# GPMC register map
Vendor: Texas Instruments
Peripheral module from a debugger description file (folder am335x).
Registers are 32-bit, access per field, no defined reset value unless marked. A register's access mark holds for its fields unless they carry their own. Offsets are as the file gives them; lines under a group give offsets from that group; [hi:lo] are bit positions; {n}, {i} and the like mark numbered series; 'fields as' and 'values as' point back to an identical list; <NAME> marks a mode.

## GPMC
0x00 GPMC_REVISION ro — The GPMC_REVISION register contains the IP revision code.
  [7:0] REV — IP revision. Major revision is [7:4]. Minor revision is [3:0]. Examples: 10h for revision 1.0, 21h for revision 2.1.
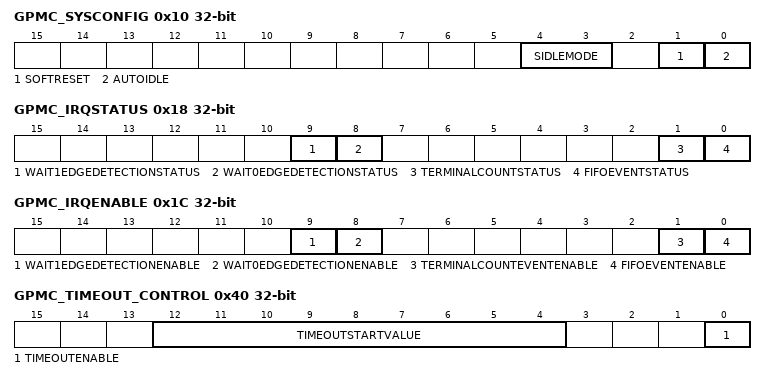
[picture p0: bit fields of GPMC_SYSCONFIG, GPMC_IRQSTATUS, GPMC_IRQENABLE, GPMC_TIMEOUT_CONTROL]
0x10 GPMC_SYSCONFIG — The GPMC_SYSCONFIG register controls the various parameters of the OCP interface.
  [4:3] SIDLEMODE rw — Idle mode
  [1] SOFTRESET rw — Software reset (Set 1 to this bit triggers a module reset. This bit is automatically reset by hardware. During reads, it always returns 0).
  [0] AUTOIDLE rw — Internal OCP clock gating strategy.
0x14 GPMC_SYSSTATUS ro — The GPMC_SYSSTATUS register provides status information about the module, excluding the interrupt status information.
  [0] RESETDONE — Internal reset monitoring
0x18 GPMC_IRQSTATUS — The GPMC_IRQSTATUS interrupt status register regroups all the status of the module internal events that can generate an interrupt.
  [9] WAIT1EDGEDETECTIONSTATUS rw — Status of the Wait1 Edge Detection interrupt
  [8] WAIT0EDGEDETECTIONSTATUS rw — Status of the Wait0 Edge Detection interrupt
  [1] TERMINALCOUNTSTATUS rw — Status of the TerminalCountEvent interrupt
  [0] FIFOEVENTSTATUS rw — Status of the FIFOEvent interrupt
0x1C GPMC_IRQENABLE — The GPMC_IRQENABLE interrupt enable register allows to mask/unmask the module internal sources of interrupt, on a event-by-event basis.
  [9] WAIT1EDGEDETECTIONENABLE rw — Enables the Wait1 Edge Detection interrupt
  [8] WAIT0EDGEDETECTIONENABLE rw — Enables the Wait0 Edge Detection interrupt
  [1] TERMINALCOUNTEVENTENABLE rw — Enables TerminalCountEvent interrupt issuing in pre-fetch or write posting mode
  [0] FIFOEVENTENABLE rw — Enables the FIFOEvent interrupt
0x40 GPMC_TIMEOUT_CONTROL — The GPMC_TIMEOUT_CONTROL register allows the user to set the start value of the timeout counter
  [12:4] TIMEOUTSTARTVALUE rw — Start value of the time-out counter (000 corresponds to 0 GPMC.FCLK cycle, 1h corresponds to 1 GPMC.FCLK cycle, and 1FFh corresponds to 511 GPMC.FCLK cycles)
  [0] TIMEOUTENABLE rw — Enable bit of the TimeOut feature
0x44 GPMC_ERR_ADDRESS — The GPMC_ERR_ADDRESS register stores the address of the illegal access when an error occurs.
  [30:0] ILLEGALADD rw — Address of illegal access: A30 (0 for memory region, 1 for GPMC register region) and A29 to A0 (1GByte maximum)
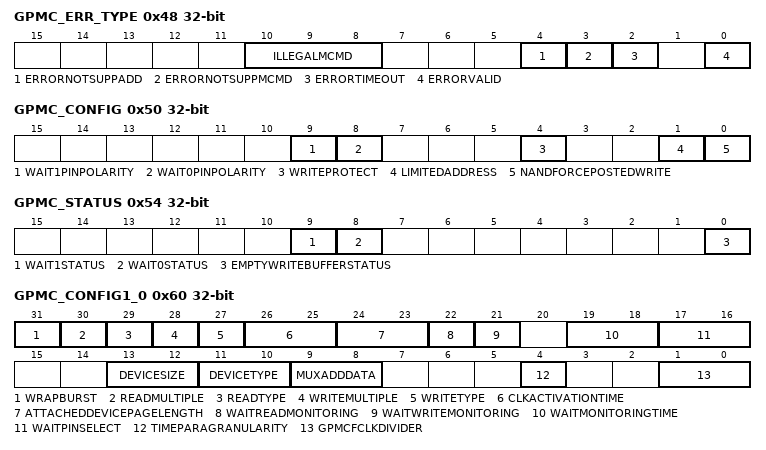
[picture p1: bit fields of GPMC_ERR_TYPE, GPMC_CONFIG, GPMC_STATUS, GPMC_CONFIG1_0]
0x48 GPMC_ERR_TYPE — The GPMC_ERR_TYPE register stores the type of error when an error occurs.
  [10:8] ILLEGALMCMD rw — System Command of the transaction that caused the error
  [4] ERRORNOTSUPPADD rw — Not supported Address error
  [3] ERRORNOTSUPPMCMD rw — Not supported Command error
  [2] ERRORTIMEOUT rw — Time-out error
  [0] ERRORVALID rw — Error validity status - Must be explicitly cleared with a write 1 transaction
0x50 GPMC_CONFIG — The configuration register allows global configuration of the GPMC.
  [9] WAIT1PINPOLARITY rw — Selects the polarity of input pin WAIT1.
  [8] WAIT0PINPOLARITY rw — Selects the polarity of input pin WAIT0.
  [4] WRITEPROTECT rw — Controls the WP output pin level.
  [1] LIMITEDADDRESS rw — Limited Address device support.
  [0] NANDFORCEPOSTEDWRITE rw
0x54 GPMC_STATUS — The status register provides global status bits of the GPMC.
  [9] WAIT1STATUS rw — Is a copy of input pin WAIT1. (Reset value is WAIT1 input pin sampled at IC reset)
  [8] WAIT0STATUS rw — Is a copy of input pin WAIT0. (Reset value is WAIT0 input pin sampled at IC reset)
  [0] EMPTYWRITEBUFFERSTATUS rw — Stores the empty status of the write buffer
0x60 GPMC_CONFIG1_0 — The configuration 1 register sets signal control parameters per chip select.
  [31] WRAPBURST rw — Enables the wrapping burst capability. Must be set if the attached device is configured in wrapping burst
  [30] READMULTIPLE rw — Selects the read single or multiple access
  [29] READTYPE rw — Selects the read mode operation
  [28] WRITEMULTIPLE rw — Selects the write single or multiple access
  [27] WRITETYPE rw — Selects the write mode operation
  [26:25] CLKACTIVATIONTIME rw — Output GPMC.CLK activation time
  [24:23] ATTACHEDDEVICEPAGELENGTH rw — Specifies the attached device page (burst) length (1 Word = Interface size)
  [22] WAITREADMONITORING rw — Selects the Wait monitoring configuration for Read accesses.
  [21] WAITWRITEMONITORING rw — Selects the Wait monitoring configuration for Write accesses
  [19:18] WAITMONITORINGTIME rw — Selects input pin Wait monitoring time
  [17:16] WAITPINSELECT rw — Selects the input WAIT pin for this chip select.
  [13:12] DEVICESIZE rw — Selects the device size attached (Reset value is SYSBOOT[8] input pin sampled at IC reset for CS[0] (active low) and 01 for CS[1] to CS[6] (active low)).
  [11:10] DEVICETYPE rw — Selects the attached device type
  [9:8] MUXADDDATA rw — Enables the Address and data multiplexed protocol (Reset value is SYSBOOT[11] and SYSBOOT[10] input pins sampled at IC reset for CS[0] (active low) and 0 for CS[1] to CS[6] (active low)).
  [4] TIMEPARAGRANULARITY rw — Signals timing latencies scalar factor (Rd/WRCycleTime, AccessTime, PageBurstAccessTime, CSOnTime, CSRd/WrOffTime, ADVOnTime, ADVRd/WrOffTime, OEOnTime, OEOffTime, WEOnTime, WEOffTime, Cycle2CycleDelay, BusTurnAround, TimeOutStartValue)
  [1:0] GPMCFCLKDIVIDER rw — Divides the GPMC.FCLK clock
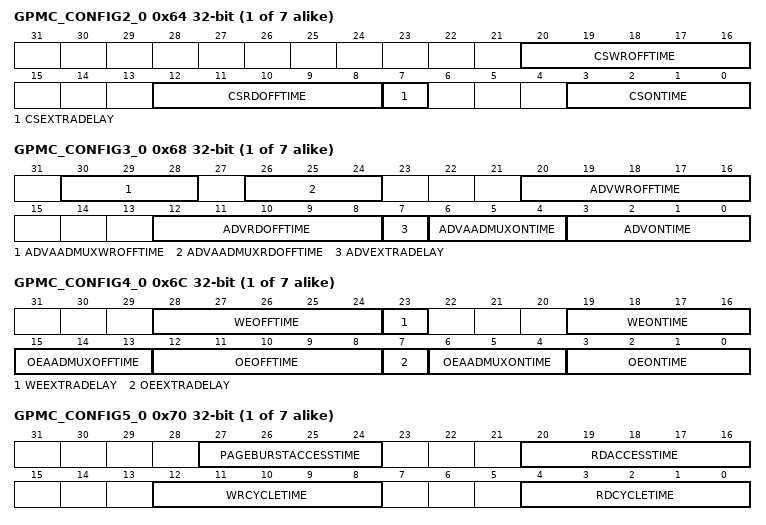
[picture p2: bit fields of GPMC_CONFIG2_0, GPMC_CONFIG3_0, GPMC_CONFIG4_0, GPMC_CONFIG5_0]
{0x64+0x30*i} GPMC_CONFIG2_{i} (i=0..6) — Chip-select signal timing parameter configuration.
  [20:16] CSWROFFTIME rw — CS# de-assertion time from start cycle time for write accesses
  [12:8] CSRDOFFTIME rw — CS# de-assertion time from start cycle time for read accesses
  [7] CSEXTRADELAY rw — CS# Add Extra Half GPMC.FCLK cycle
  [3:0] CSONTIME rw — CS# assertion time from start cycle time
{0x68+0x30*i} GPMC_CONFIG3_{i} (i=0..6) — ADV# signal timing parameter configuration.
  [30:28] ADVAADMUXWROFFTIME rw — ADV# de-assertion for first address phase when using the AAD-Mux protocol
  [26:24] ADVAADMUXRDOFFTIME rw — ADV# assertion for first address phase when using the AAD-Mux protocol
  [20:16] ADVWROFFTIME rw — ADV# de-assertion time from start cycle time for write accesses
  [12:8] ADVRDOFFTIME rw — ADV# de-assertion time from start cycle time for read accesses
  [7] ADVEXTRADELAY rw — ADV# Add Extra Half GPMC.FCLK cycle
  [6:4] ADVAADMUXONTIME rw — ADV# assertion for first address phase when using the AAD-Multiplexed protocol
  [3:0] ADVONTIME rw — ADV# assertion time from start cycle time
{0x6C+0x30*i} GPMC_CONFIG4_{i} (i=0..6) — WE# and OE# signals timing parameter configuration.
  [28:24] WEOFFTIME rw — WE# de-assertion time from start cycle time
  [23] WEEXTRADELAY rw — WE# Add Extra Half GPMC.FCLK cycle
  [19:16] WEONTIME rw — WE# assertion time from start cycle time
  [15:13] OEAADMUXOFFTIME rw — OE# de-assertion time for the first address phase in an AAD-Multiplexed access
  [12:8] OEOFFTIME rw — OE# de-assertion time from start cycle time
  [7] OEEXTRADELAY rw — OE# Add Extra Half GPMC.FCLK cycle
  [6:4] OEAADMUXONTIME rw — OE# assertion time for the first address phase in an AAD-Multiplexed access
  [3:0] OEONTIME rw — OE# assertion time from start cycle time
{0x70+0x30*i} GPMC_CONFIG5_{i} (i=0..6) — RdAccessTime and CycleTime timing parameters configuration.
  [27:24] PAGEBURSTACCESSTIME rw — Delay between successive words in a multiple access
  [20:16] RDACCESSTIME rw — Delay between start cycle time and first data valid
  [12:8] WRCYCLETIME rw — Total write cycle time
  [4:0] RDCYCLETIME rw — Total read cycle time
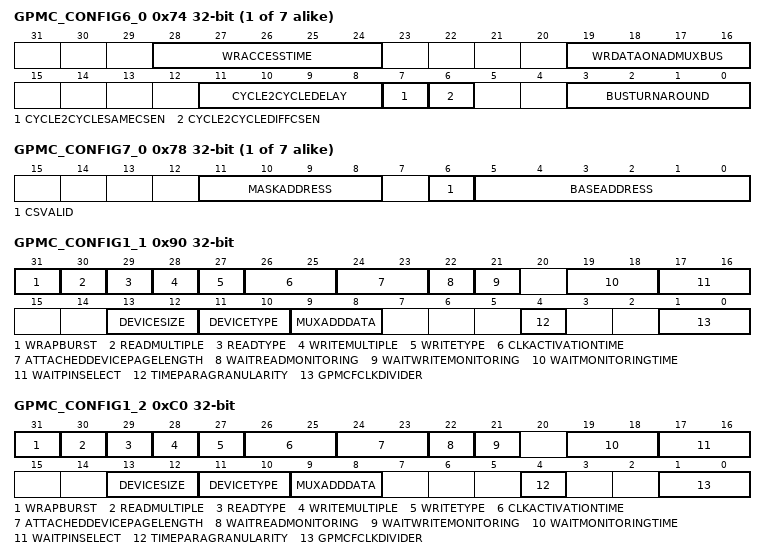
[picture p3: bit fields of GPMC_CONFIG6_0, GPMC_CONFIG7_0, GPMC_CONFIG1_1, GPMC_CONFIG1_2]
{0x74+0x30*i} GPMC_CONFIG6_{i} (i=0..6) — WrAccessTime, WrDataOnADmuxBus, Cycle2Cycle, and BusTurnAround parameters configuration
  [28:24] WRACCESSTIME rw — Delay from StartAccessTime to the GPMC.FCLK rising edge corresponding the the GPMC.CLK rising edge used by the attached memory for the first data capture
  [19:16] WRDATAONADMUXBUS rw — Specifies on which GPMC.FCLK rising edge the first data of the synchronous burst write is driven in the add/data multiplexed bus
  [11:8] CYCLE2CYCLEDELAY rw — Chip select high pulse delay between two successive accesses
  [7] CYCLE2CYCLESAMECSEN rw — Add Cycle2CycleDelay between two successive accesses to the same chip-select (any access type)
  [6] CYCLE2CYCLEDIFFCSEN rw — Add Cycle2CycleDelay between two successive accesses to a different chip-select (any access type)
  [3:0] BUSTURNAROUND rw — Bus turn around latency between two successive accesses to the same chip-select (read to write) or to a different chip-select (read to read and read to write)
{0x78+0x30*i} GPMC_CONFIG7_{i} (i=0..6) — Chip-select address mapping configuration.
  [11:8] MASKADDRESS rw — Chip-select mask address. Values not listed must be avoided as they create holes in the chip-select address space.
  [6] CSVALID rw — Chip-select enable (reset value is 1 for CS[0] (active low) and 0 for CS[1] to CS[5] (active low)).
  [5:0] BASEADDRESS rw — Chip-select base address. CSi base address where i = 0 to 3 (16 Mbytes minimum granularity). Bits 5 to 0 correspond to A29, A28, A27, A26, A25, and A24.
{0x7C+0x30*i} GPMC_NAND_COMMAND_{i} wo (i=0..6) — This register is not a true register, just an address location.
  [31:0] GPMC_NAND_COMMAND_{i} — Writing data at the GPMC_NAND_COMMAND_{i} location places the data as the NAND command value on the bus, using a regular asynchronous write access.
{0x80+0x30*i} GPMC_NAND_ADDRESS_{i} wo (i=0..6) — This register is not a true register, just an address location.
  [31:0] GPMC_NAND_ADDRESS_{i} — Writing data at the GPMC_NAND_ADDRESS_{i} location places the data as the NAND partial address value on the bus, using a regular asynchronous write access.
{0x84+0x30*i} GPMC_NAND_DATA_{i} rw (i=0..6) — This register is not a true register, just an address location.
  [31:0] GPMC_NAND_DATA_{i} — Reading data from the GPMC_NAND_DATA_{i} location or from any location in the associated chip-select memory region activates an asynchronous read access.
0x90 GPMC_CONFIG1_1 — The configuration 1 register sets signal control parameters per chip select.
  [31] WRAPBURST rw — Enables the wrapping burst capability. Must be set if the attached device is configured in wrapping burst
  [30] READMULTIPLE rw — Selects the read single or multiple access
  [29] READTYPE rw — Selects the read mode operation
  [28] WRITEMULTIPLE rw — Selects the write single or multiple access
  [27] WRITETYPE rw — Selects the write mode operation
  [26:25] CLKACTIVATIONTIME rw — Output GPMC.CLK activation time
  [24:23] ATTACHEDDEVICEPAGELENGTH rw — Specifies the attached device page (burst) length (1 Word = Interface size)
  [22] WAITREADMONITORING rw — Selects the Wait monitoring configuration for Read accesses.
  [21] WAITWRITEMONITORING rw — Selects the Wait monitoring configuration for Write accesses
  [19:18] WAITMONITORINGTIME rw — Selects input pin Wait monitoring time
  [17:16] WAITPINSELECT rw — Selects the input WAIT pin for this chip select.
  [13:12] DEVICESIZE rw — Selects the device size attached (Reset value is SYSBOOT[8] input pin sampled at IC reset for CS[0] (active low) and 01 for CS[1] to CS[6] (active low)).
  [11:10] DEVICETYPE rw — Selects the attached device type.
  [9:8] MUXADDDATA rw — Enables the Address and data multiplexed protocol (Reset value is SYSBOOT[11] and SYSBOOT[10] input pins sampled at IC reset for CS[0] (active low) and 0 for CS[1] to CS[6] (active low)).
  [4] TIMEPARAGRANULARITY rw — Signals timing latencies scalar factor (Rd/WRCycleTime, AccessTime, PageBurstAccessTime, CSOnTime, CSRd/WrOffTime, ADVOnTime, ADVRd/WrOffTime, OEOnTime, OEOffTime, WEOnTime, WEOffTime, Cycle2CycleDelay, BusTurnAround, TimeOutStartValue)
  [1:0] GPMCFCLKDIVIDER rw — Divides the GPMC.FCLK clock.
0xC0 GPMC_CONFIG1_2 — The configuration 1 register sets signal control parameters per chip select.
  [31] WRAPBURST rw — Enables the wrapping burst capability. Must be set if the attached device is configured in wrapping burst
  [30] READMULTIPLE rw — Selects the read single or multiple access
  [29] READTYPE rw — Selects the read mode operation
  [28] WRITEMULTIPLE rw — Selects the write single or multiple access
  [27] WRITETYPE rw — Selects the write mode operation
  [26:25] CLKACTIVATIONTIME rw — Output GPMC.CLK activation time
  [24:23] ATTACHEDDEVICEPAGELENGTH rw — Specifies the attached device page (burst) length (1 Word = Interface size)
  [22] WAITREADMONITORING rw — Selects the Wait monitoring configuration for Read accesses.
  [21] WAITWRITEMONITORING rw — Selects the Wait monitoring configuration for Write accesses
  [19:18] WAITMONITORINGTIME rw — Selects input pin Wait monitoring time
  [17:16] WAITPINSELECT rw — Selects the input WAIT pin for this chip select.
  [13:12] DEVICESIZE rw — Selects the device size attached (Reset value is SYSBOOT[8] input pin sampled at IC reset for CS[0] (active low) and 01 for CS[1] to CS[6] (active low)).
  [11:10] DEVICETYPE rw — Selects the attached device type.
  [9:8] MUXADDDATA rw — Enables the Address and data multiplexed protocol (Reset value is SYSBOOT[11] and SYSBOOT[10] input pins sampled at IC reset for CS[0] (active low) and 0 for CS[1] to CS[6] (active low)).
  [4] TIMEPARAGRANULARITY rw — Signals timing latencies scalar factor (Rd/WRCycleTime, AccessTime, PageBurstAccessTime, CSOnTime, CSRd/WrOffTime, ADVOnTime, ADVRd/WrOffTime, OEOnTime, OEOffTime, WEOnTime, WEOffTime, Cycle2CycleDelay, BusTurnAround, TimeOutStartValue).
  [1:0] GPMCFCLKDIVIDER rw — Divides the GPMC.FCLK clock.
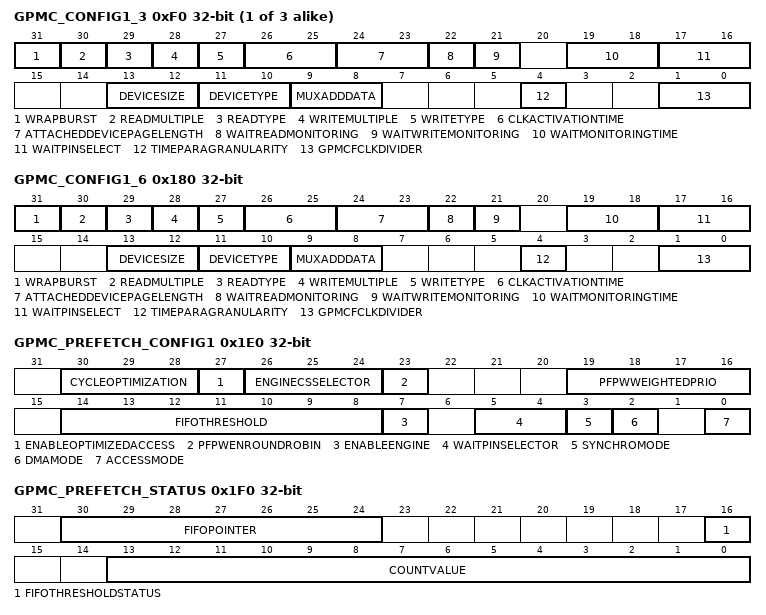
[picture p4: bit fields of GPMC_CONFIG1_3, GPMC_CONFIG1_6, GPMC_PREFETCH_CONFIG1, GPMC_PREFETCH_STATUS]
{0x60+0x30*i} GPMC_CONFIG1_{i} (i=3..5) — The configuration 1 register sets signal control parameters per chip select.
  [31] WRAPBURST rw — Enables the wrapping burst capability. Must be set if the attached device is configured in wrapping burst
  [30] READMULTIPLE rw — Selects the read single or multiple access
  [29] READTYPE rw — Selects the read mode operation
  [28] WRITEMULTIPLE rw — Selects the write single or multiple access
  [27] WRITETYPE rw — Selects the write mode operation
  [26:25] CLKACTIVATIONTIME rw — Output GPMC.CLK activation time
  [24:23] ATTACHEDDEVICEPAGELENGTH rw — Specifies the attached device page (burst) length (1 Word = Interface size)
  [22] WAITREADMONITORING rw — Selects the Wait monitoring configuration for Read accesses.
  [21] WAITWRITEMONITORING rw — Selects the Wait monitoring configuration for Write accesses
  [19:18] WAITMONITORINGTIME rw — Selects input pin Wait monitoring time
  [17:16] WAITPINSELECT rw — Selects the input WAIT pin for this chip select.
  [13:12] DEVICESIZE rw — Selects the device size attached (Reset value is SYSBOOT[8] input pin sampled at IC reset for CS[0] (active low) and 01 for CS[1] to CS[6] (active low)).
  [11:10] DEVICETYPE rw — Selects the attached device type
  [9:8] MUXADDDATA rw — Enables the Address and data multiplexed protocol (Reset value is SYSBOOT[11] and SYSBOOT[10] input pins sampled at IC reset for CS[0] (active low) and 0 for CS[1] to CS[6] (active low)).
  [4] TIMEPARAGRANULARITY rw — Signals timing latencies scalar factor (Rd/WRCycleTime, AccessTime, PageBurstAccessTime, CSOnTime, CSRd/WrOffTime, ADVOnTime, ADVRd/WrOffTime, OEOnTime, OEOffTime, WEOnTime, WEOffTime, Cycle2CycleDelay, BusTurnAround, TimeOutStartValue).
  [1:0] GPMCFCLKDIVIDER rw — Divides the GPMC.FCLK clock.
0x180 GPMC_CONFIG1_6 — The configuration 1 register sets signal control parameters per chip select.
  [31] WRAPBURST rw — Enables the wrapping burst capability. Must be set if the attached device is configured in wrapping burst
  [30] READMULTIPLE rw — Selects the read single or multiple access
  [29] READTYPE rw — Selects the read mode operation
  [28] WRITEMULTIPLE rw — Selects the write single or multiple access
  [27] WRITETYPE rw — Selects the write mode operation
  [26:25] CLKACTIVATIONTIME rw — Output GPMC.CLK activation time
  [24:23] ATTACHEDDEVICEPAGELENGTH rw — Specifies the attached device page (burst) length (1 Word = Interface size)
  [22] WAITREADMONITORING rw — Selects the Wait monitoring configuration for Read accesses.
  [21] WAITWRITEMONITORING rw — Selects the Wait monitoring configuration for Write accesses
  [19:18] WAITMONITORINGTIME rw — Selects input pin Wait monitoring time
  [17:16] WAITPINSELECT rw — Selects the input WAIT pin for this chip select.
  [13:12] DEVICESIZE rw — Selects the device size attached (Reset value is SYSBOOT[8] input pin sampled at IC reset for CS[0] (active low) and 01 for CS[1] to CS[6] (active low)).
  [11:10] DEVICETYPE rw — Selects the attached device type
  [9:8] MUXADDDATA rw — Enables the Address and data multiplexed protocol (Reset value is SYSBOOT[11] and SYSBOOT[10] input pin sampled at IC reset for CS[0] (active low) and 0 for CS[1] to CS[6] (active low)).
  [4] TIMEPARAGRANULARITY rw — Signals timing latencies scalar factor (Rd/WRCycleTime, AccessTime, PageBurstAccessTime, CSOnTime, CSRd/WrOffTime, ADVOnTime, ADVRd/WrOffTime, OEOnTime, OEOffTime, WEOnTime, WEOffTime, Cycle2CycleDelay, BusTurnAround, TimeOutStartValue).
  [1:0] GPMCFCLKDIVIDER rw — Divides the GPMC.FCLK clock.
0x1E0 GPMC_PREFETCH_CONFIG1
  [30:28] CYCLEOPTIMIZATION rw — Define the number of GPMC.FCLK cycles to be substracted from RdCycleTime, WrCycleTime, AccessTime, CSRdOffTime, CSWrOffTime, ADVRdOffTime, ADVWrOffTime, OEOffTime, WEOffTime
  [27] ENABLEOPTIMIZEDACCESS rw — Enables access cycle optimization
  [26:24] ENGINECSSELECTOR rw — Selects the CS (active low) where Prefetch Postwrite engine is active
  [23] PFPWENROUNDROBIN rw
  [19:16] PFPWWEIGHTEDPRIO rw
  [14:8] FIFOTHRESHOLD rw
  [7] ENABLEENGINE rw
  [5:4] WAITPINSELECTOR rw
  [3] SYNCHROMODE rw
  [2] DMAMODE rw
  [0] ACCESSMODE rw
0x1E4 GPMC_PREFETCH_CONFIG2
  [13:0] TRANSFERCOUNT rw — Selects the number of bytes to be read or written by the engine to the selected CS (active low)
0x1EC GPMC_PREFETCH_CONTROL
  [0] STARTENGINE rw — Resets the FIFO pointer and starts the engine
0x1F0 GPMC_PREFETCH_STATUS ro
  [30:24] FIFOPOINTER
  [16] FIFOTHRESHOLDSTATUS — Set when FIFOPointer exceeds FIFOThreshold value.
  [13:0] COUNTVALUE — Number of remaining bytes to be read or to be written by the engine according to the TransferCount value.
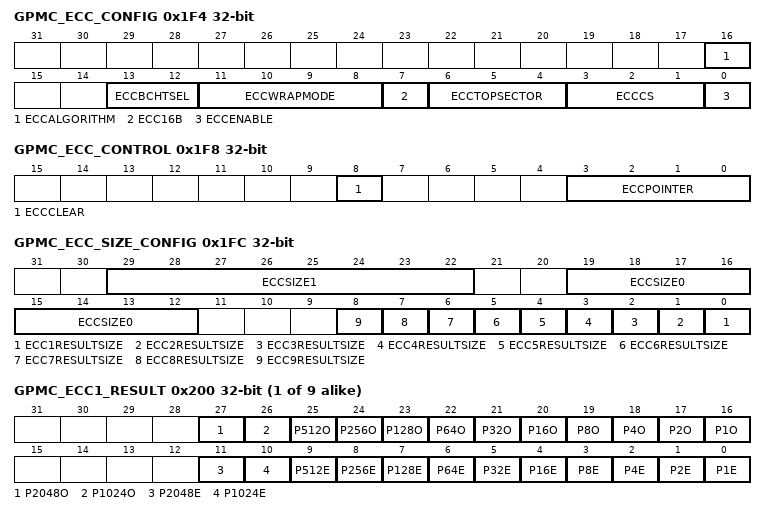
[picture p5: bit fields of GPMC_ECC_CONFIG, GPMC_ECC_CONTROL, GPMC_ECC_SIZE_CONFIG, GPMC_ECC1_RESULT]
0x1F4 GPMC_ECC_CONFIG
  [16] ECCALGORITHM rw — ECC algorithm used
  [13:12] ECCBCHTSEL rw — Error correction capability used for BCH
  [11:8] ECCWRAPMODE rw — Spare area organization definition for the BCH algorithm. See the BCH syndrome/parity calculator module functional specification for more details
  [7] ECC16B rw — Selects an ECC calculated on 16 columns
  [6:4] ECCTOPSECTOR rw — Number of sectors to process with the BCH algorithm
  [3:1] ECCCS rw — Selects the Chip-select where ECC is computed
  [0] ECCENABLE rw — Enables the ECC feature
0x1F8 GPMC_ECC_CONTROL
  [8] ECCCLEAR rw — Clear all ECC result registers
  [3:0] ECCPOINTER rw — Selects ECC result register (Reads to this field give the dynamic position of the ECC pointer - Writes to this field select the ECC result register where the first ECC computation will be stored). Writing values not listed disables the ECC engine (ECCEnable bit of GPMC_ECC_CONFIG cleared to 0).
0x1FC GPMC_ECC_SIZE_CONFIG
  [29:22] ECCSIZE1 rw — Defines ECC size 1
  [19:12] ECCSIZE0 rw — Defines ECC size 0
  [n-1] ECC{n}RESULTSIZE rw (n=1..9) — Selects ECC size for ECC {n} result register
{0x1FC+4i} GPMC_ECC{i}_RESULT ro (i=1..9)
  [27] P2048O — Odd Row Parity bit 2048, only used for ECC computed on 512 Bytes
  [26] P1024O — Odd Row Parity bit 1024
  [25] P512O — Odd Row Parity bit 512
  [24] P256O — Odd Row Parity bit 256
  [23] P128O — Odd Row Parity bit 128
  [22] P64O — Odd Row Parity bit 64
  [21] P32O — Odd Row Parity bit 32
  [20] P16O — Odd Row Parity bit 16
  [19] P8O — Odd Row Parity bit 8
  [18] P4O — Odd Column Parity bit 4
  [17] P2O — Odd Column Parity bit 2
  [16] P1O — Odd Column Parity bit 1
  [11] P2048E — Even Row Parity bit 2048, only used for ECC computed on 512 Bytes
  [10] P1024E — Even Row Parity bit 1024
  [9] P512E — Even Row Parity bit 512
  [8] P256E — Even Row Parity bit 256
  [7] P128E — Even Row Parity bit 128
  [6] P64E — Even Row Parity bit 64
  [5] P32E — Even Row Parity bit 32
  [4] P16E — Even Row Parity bit 16
  [3] P8E — Even Row Parity bit 8
  [2] P4E — Even Column Parity bit 4
  [1] P2E — Even Column Parity bit 2
  [0] P1E — Even Column Parity bit 1
{0x240+0x10*i} GPMC_BCH_RESULT0_{i} rw (i=0..6)
  [31:0] BCH_RESULT0_{i} — BCH ECC result, bits 0 to 31
{0x244+0x10*i} GPMC_BCH_RESULT1_{i} rw (i=0..6)
  [31:0] BCH_RESULT1_{i} — BCH ECC result, bits 32 to 63
{0x248+0x10*i} GPMC_BCH_RESULT2_{i} rw (i=0..6)
  [31:0] BCH_RESULT2_{i} — BCH ECC result, bits 64 to 95
{0x24C+0x10*i} GPMC_BCH_RESULT3_{i} rw (i=0..6)
  [31:0] BCH_RESULT3_{i} — BCH ECC result, bits 96 to 127
0x2D0 GPMC_BCH_SWDATA — This register is used to directly pass data to the BCH ECC calculator without accessing the actual NAND flash interface.
  [15:0] BCH_DATA rw — Data to be included in the BCH calculation. Only bits 0 to 7 are taken into account, if the calculator is configured to use 8 bits data (GPMC_ECC_CONFIG[7] ECC16B = 0).
{0x300+0x10*i} GPMC_BCH_RESULT4_{i} rw (i=0..7)
  [31:0] BCH_RESULT4_{i} — BCH ECC result, bits 128 to 159
{0x304+0x10*i} GPMC_BCH_RESULT5_{i} rw (i=0..7)
  [31:0] BCH_RESULT5_{i} — BCH ECC result, bits 160 to 191
{0x308+0x10*i} GPMC_BCH_RESULT6_{i} rw (i=0..7)
  [31:0] BCH_RESULT6_{i} — BCH ECC result, bits 192 to 207
